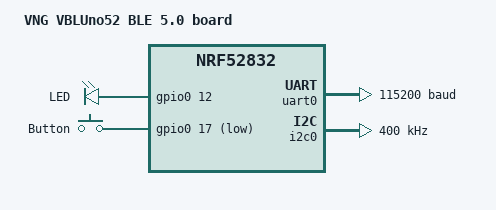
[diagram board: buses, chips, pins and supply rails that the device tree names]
/*
 * Copyright (c) 2017 VNG IoT Lab Limited
 *
 * SPDX-License-Identifier: Apache-2.0
 */

/dts-v1/;
#include <nordic/nrf52832_qfaa.dtsi>
#include "nrf52_vbluno52-pinctrl.dtsi"

/ {
	model = "VNG VBLUno52 BLE 5.0 board";
	compatible = "vng,vbluno52";

	chosen {
		zephyr,console = &uart0;
		zephyr,shell-uart = &uart0;
		zephyr,bt-mon-uart = &uart0;
		zephyr,bt-c2h-uart = &uart0;
		zephyr,sram = &sram0;
		zephyr,flash = &flash0;
	};

	/* These aliases are provided for compatibility with samples */
	aliases {
		led0 = &led0;
		sw0 = &button0;
		watchdog0 = &wdt0;
	};

	leds {
		compatible = "gpio-leds";
		/* Green LED */
		led0: led_0 {
			gpios = <&gpio0 12 0>;
			label = "LED";
		};
	};

	buttons {
		compatible = "gpio-keys";
		button0: button_0 {
			/* gpio flags need validation */
			gpios = <&gpio0 17 GPIO_ACTIVE_LOW>;
			label = "Button";
		};
	};
};

&gpiote {
	status = "okay";
};

&gpio0 {
	status = "okay";
};

&uart0 {
	status = "okay";
	compatible = "nordic,nrf-uart";
	current-speed = <115200>;
	pinctrl-0 = <&uart0_default>;
	pinctrl-1 = <&uart0_sleep>;
	pinctrl-names = "default", "sleep";
};

&i2c0 {
	compatible = "nordic,nrf-twim";
	status = "okay";
	clock-frequency = <I2C_BITRATE_FAST>;
	pinctrl-0 = <&i2c0_default>;
	pinctrl-1 = <&i2c0_sleep>;
	pinctrl-names = "default", "sleep";
};
